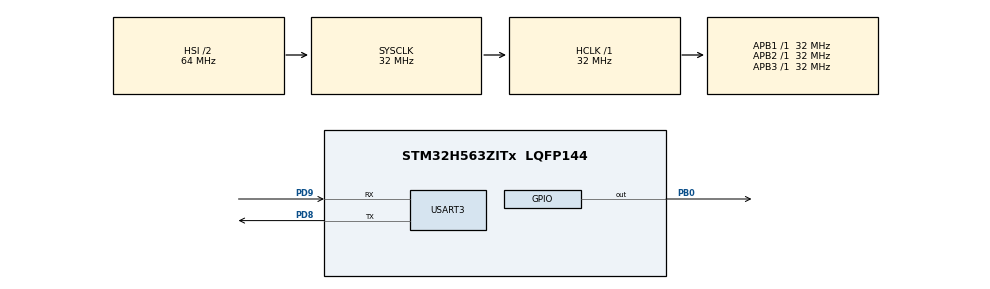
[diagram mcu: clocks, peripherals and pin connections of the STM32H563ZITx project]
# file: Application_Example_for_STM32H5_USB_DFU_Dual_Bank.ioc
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BOOTPATH.BootPathName=LEGACY
BOOTPATH.UserSelectedBootPath=LEGACY
CORTEX_M33_NS.userName=CORTEX_M33
Mcu.Family=STM32H5
Mcu.Name=STM32H563ZITx
Mcu.Package=LQFP144
NVIC.PriorityGroup=NVIC_PRIORITYGROUP_4
PB0.Signal=GPIO_Output
PD8.Mode=Asynchronous
PD8.Signal=USART3_TX
PD9.Mode=Asynchronous
PD9.Signal=USART3_RX
ProjectManager.HeapSize=0x200
ProjectManager.StackSize=0x400
ProjectManager.TargetToolchain=STM32CubeIDE
RCC.ADCFreq_Value=32000000
RCC.AHBFreq_Value=32000000
RCC.APB1Freq_Value=32000000
RCC.APB1TimFreq_Value=32000000
RCC.APB2Freq_Value=32000000
RCC.APB2TimFreq_Value=32000000
RCC.APB3Freq_Value=32000000
RCC.CSI_VALUE=4000000
RCC.CortexFreq_Value=32000000
RCC.EPOD_VALUE=4000000
RCC.HCLKFreq_Value=32000000
RCC.HSE_VALUE=25000000
RCC.HSI48_VALUE=48000000
RCC.HSI_VALUE=64000000
RCC.LSE_VALUE=32768
RCC.LSIRC_VALUE=32000
RCC.SYSCLKFreq_VALUE=32000000
RCC.USBFreq_Value=48000000
RCC.VCOOutputFreq_Value=516000000
USART3.VirtualMode-Asynchronous=VM_ASYNC
VP_BOOTPATH_VS_BOOTPATH.Mode=BP_Activate
VP_CORTEX_M33_NS_VS_Hclk.Mode=Hclk_Mode
VP_MEMORYMAP_VS_MEMORYMAP.Mode=CurAppReg
VP_PWR_VS_DBSignals.Mode=DisableDeadBatterySignals
VP_PWR_VS_LPOM.Mode=PowerOptimisation
VP_PWR_VS_SECSignals.Mode=Security/Privilege
board=custom

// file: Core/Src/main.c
/* USER CODE BEGIN Header */
/**
  ******************************************************************************
  * @file           : main.c
  * @brief          : Main program body
  ******************************************************************************
  * @attention
  *
  * Copyright (c) 2024 STMicroelectronics.
  * All rights reserved.
  *
  * This software is licensed under terms that can be found in the LICENSE file
  * in the root directory of this software component.
  * If no LICENSE file comes with this software, it is provided AS-IS.
  *
  ******************************************************************************
  */
/* USER CODE END Header */
#include "main.h"

/* USER CODE BEGIN PD */
#define PUTCHAR_PROTOTYPE int __io_putchar(int ch)
/* USER CODE END PD */

UART_HandleTypeDef huart3;

void SystemClock_Config(void);
static void MX_GPIO_Init(void);
static void MX_USART3_UART_Init(void);

int main(void)
{

  /* USER CODE BEGIN 1 */
	SCB->VTOR = 0x08022000;
  /* USER CODE END 1 */

  /* MCU Configuration--------------------------------------------------------*/

  /* Reset of all peripherals, Initializes the Flash interface and the Systick. */
  HAL_Init();

  /* Configure the system clock */
  SystemClock_Config();

  /* Initialize all configured peripherals */
  MX_GPIO_Init();
  MX_USART3_UART_Init();
  /* USER CODE BEGIN 2 */
  printf("\nBooting Application Code\n");
  /* USER CODE END 2 */

  /* Infinite loop */
  /* USER CODE BEGIN WHILE */
  while (1)
  {

	HAL_GPIO_TogglePin(GPIOB, GPIO_PIN_0);
	HAL_Delay(1000);
	printf("Application Running\n");

    /* USER CODE END WHILE */

  }
}

void SystemClock_Config(void)
{
  RCC_OscInitTypeDef RCC_OscInitStruct = {0};
  RCC_ClkInitTypeDef RCC_ClkInitStruct = {0};

  /** Configure the main internal regulator output voltage
  */
  __HAL_PWR_VOLTAGESCALING_CONFIG(PWR_REGULATOR_VOLTAGE_SCALE3);

  while(!__HAL_PWR_GET_FLAG(PWR_FLAG_VOSRDY)) {}

  /** Initializes the RCC Oscillators according to the specified parameters
  * in the RCC_OscInitTypeDef structure.
  */
  RCC_OscInitStruct.OscillatorType = RCC_OSCILLATORTYPE_HSI;
  RCC_OscInitStruct.HSIState = RCC_HSI_ON;
  RCC_OscInitStruct.HSIDiv = RCC_HSI_DIV2;
  RCC_OscInitStruct.HSICalibrationValue = RCC_HSICALIBRATION_DEFAULT;
  RCC_OscInitStruct.PLL.PLLState = RCC_PLL_NONE;
  if (HAL_RCC_OscConfig(&RCC_OscInitStruct) != HAL_OK)
  {
    Error_Handler();
  }

  /** Initializes the CPU, AHB and APB buses clocks
  */
  RCC_ClkInitStruct.ClockType = RCC_CLOCKTYPE_HCLK|RCC_CLOCKTYPE_SYSCLK
                              |RCC_CLOCKTYPE_PCLK1|RCC_CLOCKTYPE_PCLK2
                              |RCC_CLOCKTYPE_PCLK3;
  RCC_ClkInitStruct.SYSCLKSource = RCC_SYSCLKSOURCE_HSI;
  RCC_ClkInitStruct.AHBCLKDivider = RCC_SYSCLK_DIV1;
  RCC_ClkInitStruct.APB1CLKDivider = RCC_HCLK_DIV1;
  RCC_ClkInitStruct.APB2CLKDivider = RCC_HCLK_DIV1;
  RCC_ClkInitStruct.APB3CLKDivider = RCC_HCLK_DIV1;

  if (HAL_RCC_ClockConfig(&RCC_ClkInitStruct, FLASH_LATENCY_1) != HAL_OK)
  {
    Error_Handler();
  }

  /** Configure the programming delay
  */
  __HAL_FLASH_SET_PROGRAM_DELAY(FLASH_PROGRAMMING_DELAY_0);
}

static void MX_USART3_UART_Init(void)
{

  huart3.Instance = USART3;
  huart3.Init.BaudRate = 115200;
  huart3.Init.WordLength = UART_WORDLENGTH_8B;
  huart3.Init.StopBits = UART_STOPBITS_1;
  huart3.Init.Parity = UART_PARITY_NONE;
  huart3.Init.Mode = UART_MODE_TX_RX;
  huart3.Init.HwFlowCtl = UART_HWCONTROL_NONE;
  huart3.Init.OverSampling = UART_OVERSAMPLING_16;
  huart3.Init.OneBitSampling = UART_ONE_BIT_SAMPLE_DISABLE;
  huart3.Init.ClockPrescaler = UART_PRESCALER_DIV1;
  huart3.AdvancedInit.AdvFeatureInit = UART_ADVFEATURE_NO_INIT;
  if (HAL_UART_Init(&huart3) != HAL_OK)
  {
    Error_Handler();
  }
  if (HAL_UARTEx_SetTxFifoThreshold(&huart3, UART_TXFIFO_THRESHOLD_1_8) != HAL_OK)
  {
    Error_Handler();
  }
  if (HAL_UARTEx_SetRxFifoThreshold(&huart3, UART_RXFIFO_THRESHOLD_1_8) != HAL_OK)
  {
    Error_Handler();
  }
  if (HAL_UARTEx_DisableFifoMode(&huart3) != HAL_OK)
  {
    Error_Handler();
  }

}

static void MX_GPIO_Init(void)
{
  GPIO_InitTypeDef GPIO_InitStruct = {0};

  /* GPIO Ports Clock Enable */
  __HAL_RCC_GPIOB_CLK_ENABLE();
  __HAL_RCC_GPIOD_CLK_ENABLE();

  /*Configure GPIO pin Output Level */
  HAL_GPIO_WritePin(GPIOB, GPIO_PIN_0, GPIO_PIN_RESET);

  /*Configure GPIO pin : PB0 */
  GPIO_InitStruct.Pin = GPIO_PIN_0;
  GPIO_InitStruct.Mode = GPIO_MODE_OUTPUT_PP;
  GPIO_InitStruct.Pull = GPIO_NOPULL;
  GPIO_InitStruct.Speed = GPIO_SPEED_FREQ_LOW;
  HAL_GPIO_Init(GPIOB, &GPIO_InitStruct);

}

/* USER CODE BEGIN 4 */
PUTCHAR_PROTOTYPE
{
  HAL_UART_Transmit(&huart3, (uint8_t *)&ch, 1, 0xFFFF);
  return ch;
}

/* USER CODE END 4 */

void Error_Handler(void)
{
  __disable_irq();
  while (1)
  {
  }
}
